# nrf9120_MLM1 register map
Vendor: Nordic Semiconductor; Series: nrf91; File version: 1
CPU: CM4 r0p1, little endian, MPU, FPU, 3 interrupt priority bits
Registers are 32-bit, read-write, reset 0x0 unless marked. A register's access mark holds for its fields unless they carry their own. Offsets are from the block's base; [hi:lo] are bit positions; lines under a group give offsets from that group; {n}, {i} and the like mark numbered series; 'fields as' and 'values as' point back to an identical list.

## TIMER0 — Timer/Counter 0
Base 0x4000C000
Same registers: TIMER1 0x4000D000, TIMER2 0x4000E000
0x00 TASKS_START wo — Start Timer
0x04 TASKS_STOP wo — Stop Timer
0x08 TASKS_COUNT wo — Increment Timer (Counter mode only)
0x0C TASKS_CLEAR wo — Clear time
0x10 TASKS_SHUTDOWN wo — Deprecated register - Shut down timer
{0x40+4i} TASKS_CAPTURE[{i}] (i=0..5) wo — Description collection[0]: Capture Timer value to CC[0] register
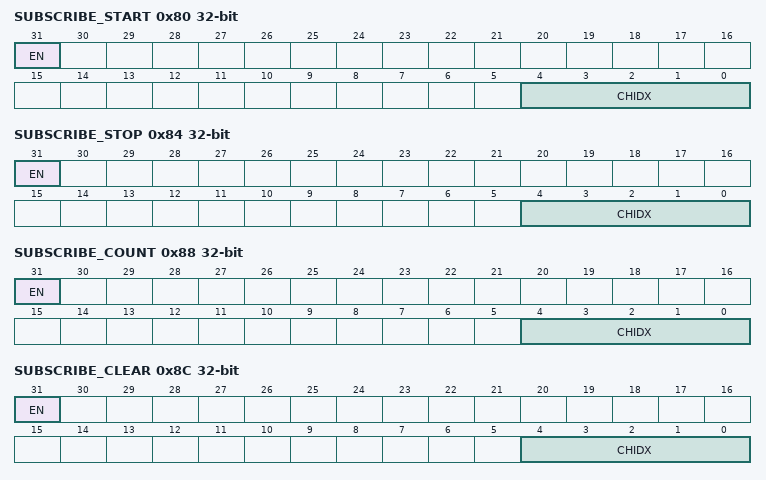
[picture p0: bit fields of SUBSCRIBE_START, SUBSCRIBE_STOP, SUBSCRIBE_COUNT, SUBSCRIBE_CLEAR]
0x80 SUBSCRIBE_START — Subscribe configuration for TASKS_START
  [31] EN
    0=Disabled (Disable subscription); 1=Enabled (Enable subscription)
  [4:0] CHIDX — Channel the TASKS_START will subscribe to.
0x84 SUBSCRIBE_STOP — Subscribe configuration for TASKS_STOP
  [31] EN
    values as SUBSCRIBE_START.EN
  [4:0] CHIDX — Channel the TASKS_STOP will subscribe to.
0x88 SUBSCRIBE_COUNT — Subscribe configuration for TASKS_COUNT
  [31] EN
    values as SUBSCRIBE_START.EN
  [4:0] CHIDX — Channel the TASKS_COUNT will subscribe to.
0x8C SUBSCRIBE_CLEAR — Subscribe configuration for TASKS_CLEAR
  [31] EN
    values as SUBSCRIBE_START.EN
  [4:0] CHIDX — Channel the TASKS_CLEAR will subscribe to.
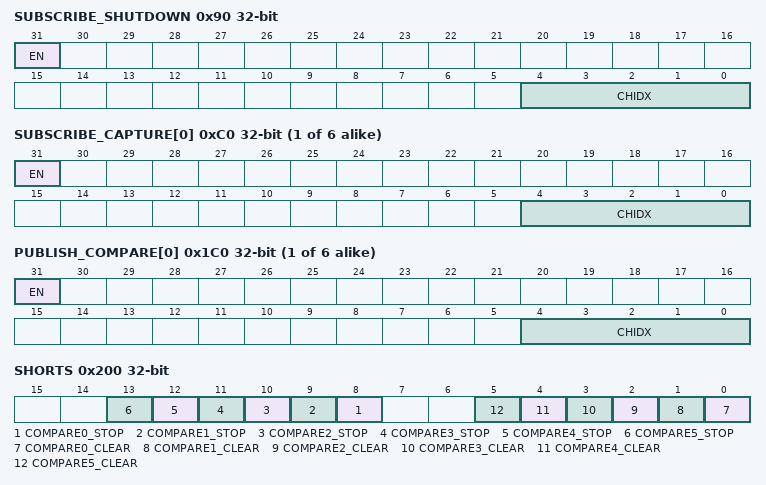
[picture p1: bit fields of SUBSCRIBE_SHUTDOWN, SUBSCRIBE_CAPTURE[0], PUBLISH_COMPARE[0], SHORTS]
0x90 SUBSCRIBE_SHUTDOWN — Subscribe configuration for TASKS_SHUTDOWN
  [31] EN
    values as SUBSCRIBE_START.EN
  [4:0] CHIDX — Channel the TASKS_SHUTDOWN will subscribe to.
{0xC0+4i} SUBSCRIBE_CAPTURE[{i}] (i=0..5) — Description collection[0]: Subscribe configuration for TASKS_CAPTURE[0]
  [31] EN
    values as SUBSCRIBE_START.EN
  [4:0] CHIDX — Channel the TASKS_CAPTURE[0] will subscribe to.
{0x140+4i} EVENTS_COMPARE[{i}] (i=0..5) — Description collection[0]: Compare event on CC[0] match
{0x1C0+4i} PUBLISH_COMPARE[{i}] (i=0..5) — Description collection[0]: Publish configuration for EVENTS_COMPARE[0]
  [31] EN
    0=Disabled (Disable publishing); 1=Enabled (Enable publishing)
  [4:0] CHIDX — Channel the EVENTS_COMPARE[0] will subscribe to.
0x200 SHORTS — Shortcut register
  [all] fields
    0=Disabled (Disable shortcut); 1=Enabled (Enable shortcut)
  [n+8] COMPARE{n}_STOP (n=0..5) — Shortcut between COMPARE[{n}] event and STOP task
  [n] COMPARE{n}_CLEAR (n=0..5) — Shortcut between COMPARE[{n}] event and CLEAR task
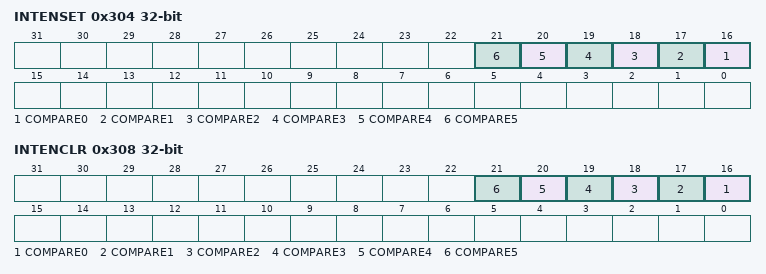
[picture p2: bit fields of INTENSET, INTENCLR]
0x304 INTENSET — Enable interrupt
  [all] fields
    on read: 0=Disabled (Read: Disabled); 1=Enabled (Read: Enabled) | on write: 1=Set (Enable)
  [n+16] COMPARE{n} (n=0..5) — Write '1' to Enable interrupt for COMPARE[{n}] event
0x308 INTENCLR — Disable interrupt
  [all] fields
    on read: 0=Disabled (Read: Disabled); 1=Enabled (Read: Enabled) | on write: 1=Clear (Disable)
  [n+16] COMPARE{n} (n=0..5) — Write '1' to Disable interrupt for COMPARE[{n}] event
0x504 MODE — Timer mode selection
  [1:0] MODE — Timer mode
    0=Timer (Select Timer mode); 1=Counter (Deprecated enumerator - Select Counter mode); 2=LowPowerCounter (Select Low Power Counter mode)
0x508 BITMODE — Configure the number of bits used by the TIMER
  [1:0] BITMODE — Timer bit width
    0=16 bit timer bit width; 1=08Bit (8 bit timer bit width); 2=24 bit timer bit width; 3=32 bit timer bit width
0x510 PRESCALER reset 0x4 — Timer prescaler register
  [3:0] PRESCALER — Prescaler value
{0x540+4i} CC[{i}] (i=0..5) — Description collection[0]: Capture/Compare register 0
  [31:0] CC — Capture/Compare value
0xFFC POWER reset 0x1 — Peripheral power control
  [0] POWER — Peripheral power control. The peripheral and its registers will be reset to its initial state by switching the peripheral off and then back on again.
    0=Disabled (Peripheral is powered off); 1=Enabled (Peripheral is powered on)

## DPPIC — Distributed Programmable Peripheral Interconnect Controller
Base 0x40010000
{0x0+8i} TASKS_CHG[{i}] (i=0..5) group — Channel group tasks
  0x00 EN wo — Description cluster[0]: Enable channel group 0
  0x04 DIS wo — Description cluster[0]: Disable channel group 0
{0x80+8i} SUBSCRIBE_CHG[{i}] (i=0..5) group — Unspecified
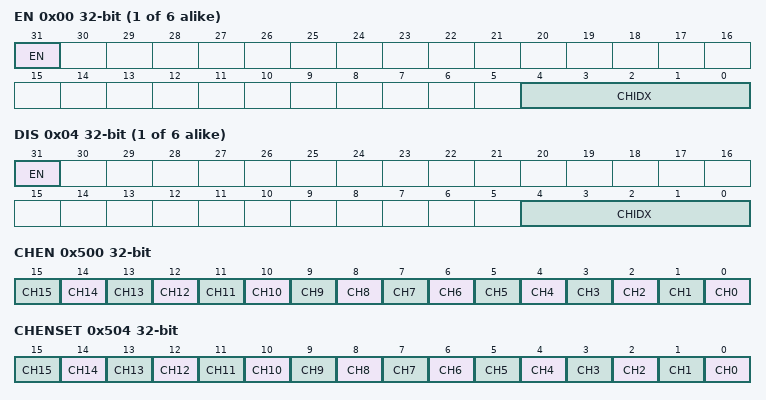
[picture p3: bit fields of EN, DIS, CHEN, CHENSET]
  0x00 EN — Description cluster[0]: Subscribe configuration for TASKS_CHG[0].EN
    [31] EN
      0=Disabled (Disable subscription); 1=Enabled (Enable subscription)
    [4:0] CHIDX — Channel the TASKS_CHG[0].EN will subscribe to.
  0x04 DIS — Description cluster[0]: Subscribe configuration for TASKS_CHG[0].DIS
    [31] EN
      values as SUBSCRIBE_CHG[0].EN.EN
    [4:0] CHIDX — Channel the TASKS_CHG[0].DIS will subscribe to.
0x500 CHEN — Channel enable register
  [all] fields
    0=Disabled (Disable channel); 1=Enabled (Enable channel)
  [n] CH{n} (n=0..15) — Enable or disable channel {n}
0x504 CHENSET write-1-sets — Channel enable set register
  [all] fields
    on read: 0=Disabled (Read: channel disabled); 1=Enabled (Read: channel enabled) | on write: 1=Set (Write: Enable channel)
  [n] CH{n} (n=0..15) — Channel {n} enable set register. Writing '0' has no effect
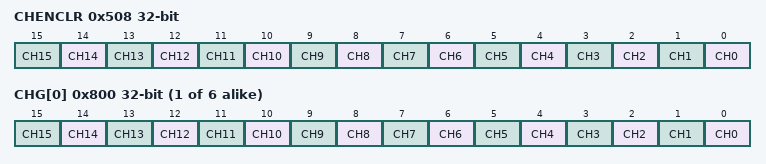
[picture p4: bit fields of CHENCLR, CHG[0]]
0x508 CHENCLR write-1-clears — Channel enable clear register
  [all] fields
    on read: 0=Disabled (Read: channel disabled); 1=Enabled (Read: channel enabled) | on write: 1=Clear (Write: disable channel)
  [n] CH{n} (n=0..15) — Channel {n} enable clear register. Writing '0' has no effect
{0x800+4i} CHG[{i}] (i=0..5) — Description collection[0]: Channel group 0
  [all] fields
    0=Excluded; 1=Included
  [n] CH{n} (n=0..15) — Include or exclude channel {n}
